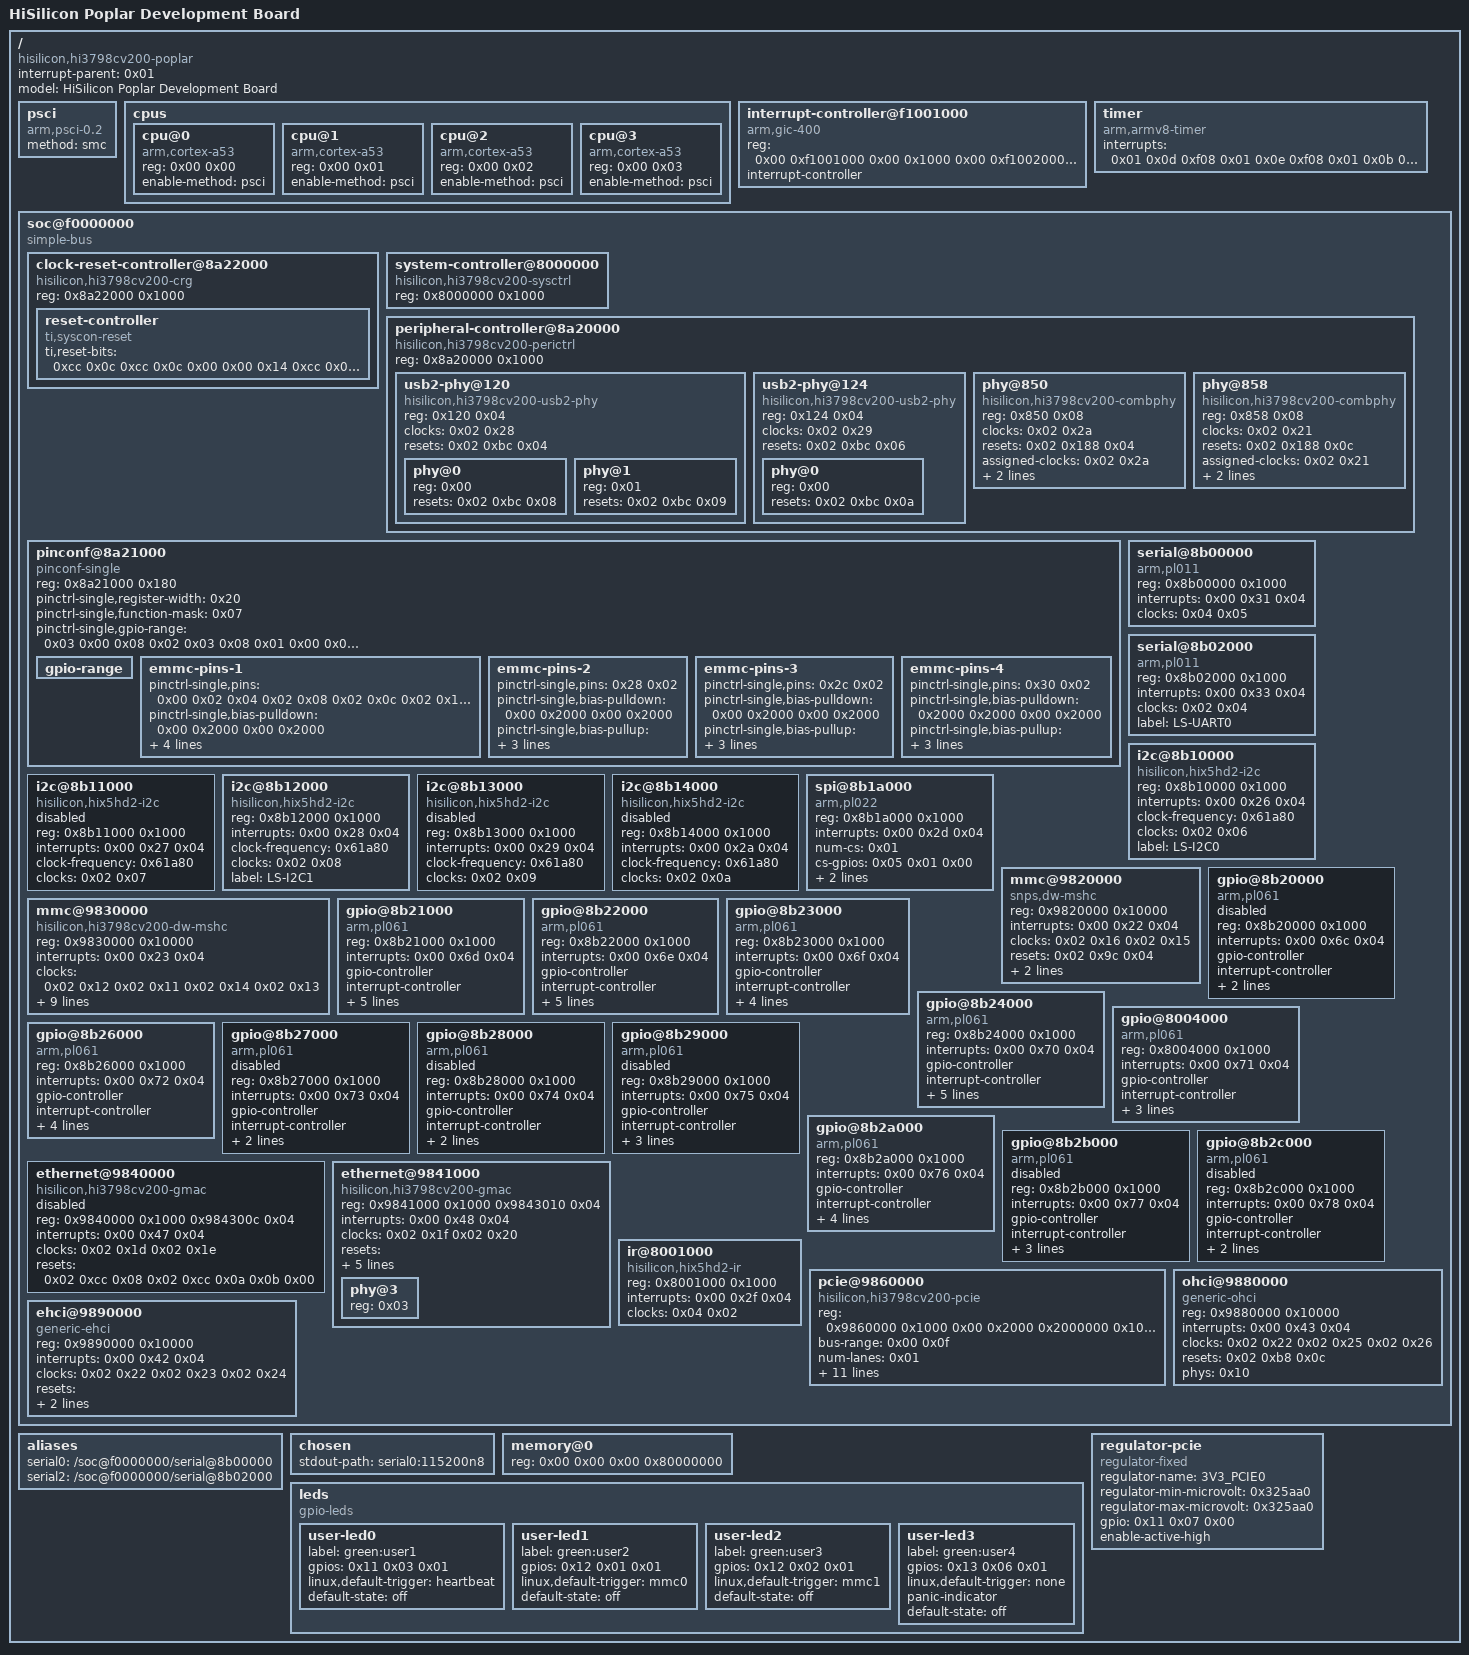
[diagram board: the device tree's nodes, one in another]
/dts-v1/;

/ {
	compatible = "hisilicon,hi3798cv200-poplar\0hisilicon,hi3798cv200";
	interrupt-parent = <0x01>;
	#address-cells = <0x02>;
	#size-cells = <0x02>;
	model = "HiSilicon Poplar Development Board";

	psci {
		compatible = "arm,psci-0.2";
		method = "smc";
	};

	cpus {
		#address-cells = <0x02>;
		#size-cells = <0x00>;

		cpu@0 {
			compatible = "arm,cortex-a53";
			device_type = "cpu";
			reg = <0x00 0x00>;
			enable-method = "psci";
		};

		cpu@1 {
			compatible = "arm,cortex-a53";
			device_type = "cpu";
			reg = <0x00 0x01>;
			enable-method = "psci";
		};

		cpu@2 {
			compatible = "arm,cortex-a53";
			device_type = "cpu";
			reg = <0x00 0x02>;
			enable-method = "psci";
		};

		cpu@3 {
			compatible = "arm,cortex-a53";
			device_type = "cpu";
			reg = <0x00 0x03>;
			enable-method = "psci";
		};
	};

	interrupt-controller@f1001000 {
		compatible = "arm,gic-400";
		reg = <0x00 0xf1001000 0x00 0x1000 0x00 0xf1002000 0x00 0x100>;
		#address-cells = <0x00>;
		#interrupt-cells = <0x03>;
		interrupt-controller;
		phandle = <0x01>;
	};

	timer {
		compatible = "arm,armv8-timer";
		interrupts = <0x01 0x0d 0xf08 0x01 0x0e 0xf08 0x01 0x0b 0xf08 0x01 0x0a 0xf08>;
	};

	soc@f0000000 {
		compatible = "simple-bus";
		#address-cells = <0x01>;
		#size-cells = <0x01>;
		ranges = <0x00 0x00 0xf0000000 0x10000000>;
		phandle = <0x14>;

		clock-reset-controller@8a22000 {
			compatible = "hisilicon,hi3798cv200-crg\0syscon\0simple-mfd";
			reg = <0x8a22000 0x1000>;
			#clock-cells = <0x01>;
			#reset-cells = <0x02>;
			phandle = <0x02>;

			reset-controller {
				compatible = "ti,syscon-reset";
				#reset-cells = <0x01>;
				ti,reset-bits = <0xcc 0x0c 0xcc 0x0c 0x00 0x00 0x14 0xcc 0x0d 0xcc 0x0d 0x00 0x00 0x14>;
				phandle = <0x0b>;
			};
		};

		system-controller@8000000 {
			compatible = "hisilicon,hi3798cv200-sysctrl\0syscon";
			reg = <0x8000000 0x1000>;
			#clock-cells = <0x01>;
			#reset-cells = <0x02>;
			phandle = <0x04>;
		};

		peripheral-controller@8a20000 {
			compatible = "hisilicon,hi3798cv200-perictrl\0syscon\0simple-mfd";
			reg = <0x8a20000 0x1000>;
			#address-cells = <0x01>;
			#size-cells = <0x01>;
			ranges = <0x00 0x8a20000 0x1000>;
			phandle = <0x15>;

			usb2-phy@120 {
				compatible = "hisilicon,hi3798cv200-usb2-phy";
				reg = <0x120 0x04>;
				clocks = <0x02 0x28>;
				resets = <0x02 0xbc 0x04>;
				#address-cells = <0x01>;
				#size-cells = <0x00>;
				phandle = <0x16>;

				phy@0 {
					reg = <0x00>;
					#phy-cells = <0x00>;
					resets = <0x02 0xbc 0x08>;
					phandle = <0x10>;
				};

				phy@1 {
					reg = <0x01>;
					#phy-cells = <0x00>;
					resets = <0x02 0xbc 0x09>;
					phandle = <0x17>;
				};
			};

			usb2-phy@124 {
				compatible = "hisilicon,hi3798cv200-usb2-phy";
				reg = <0x124 0x04>;
				clocks = <0x02 0x29>;
				resets = <0x02 0xbc 0x06>;
				#address-cells = <0x01>;
				#size-cells = <0x00>;
				phandle = <0x18>;

				phy@0 {
					reg = <0x00>;
					#phy-cells = <0x00>;
					resets = <0x02 0xbc 0x0a>;
					phandle = <0x19>;
				};
			};

			phy@850 {
				compatible = "hisilicon,hi3798cv200-combphy";
				reg = <0x850 0x08>;
				#phy-cells = <0x01>;
				clocks = <0x02 0x2a>;
				resets = <0x02 0x188 0x04>;
				assigned-clocks = <0x02 0x2a>;
				assigned-clock-rates = <0x5f5e100>;
				hisilicon,fixed-mode = <0x04>;
				phandle = <0x1a>;
			};

			phy@858 {
				compatible = "hisilicon,hi3798cv200-combphy";
				reg = <0x858 0x08>;
				#phy-cells = <0x01>;
				clocks = <0x02 0x21>;
				resets = <0x02 0x188 0x0c>;
				assigned-clocks = <0x02 0x21>;
				assigned-clock-rates = <0x5f5e100>;
				hisilicon,mode-select-bits = <0x08 0x0b 0x1800>;
				phandle = <0x0d>;
			};
		};

		pinconf@8a21000 {
			compatible = "pinconf-single";
			reg = <0x8a21000 0x180>;
			pinctrl-single,register-width = <0x20>;
			pinctrl-single,function-mask = <0x07>;
			pinctrl-single,gpio-range = <0x03 0x00 0x08 0x02 0x03 0x08 0x01 0x00 0x03 0x09 0x04 0x02 0x03 0x0d 0x01 0x00 0x03 0x0e 0x01 0x01 0x03 0x0f 0x01 0x00 0x03 0x10 0x05 0x00 0x03 0x15 0x03 0x01 0x03 0x18 0x04 0x01 0x03 0x1c 0x02 0x02 0x03 0x56 0x01 0x01 0x03 0x57 0x01 0x00 0x03 0x1e 0x04 0x02 0x03 0x22 0x03 0x00 0x03 0x25 0x01 0x02 0x03 0x26 0x03 0x02 0x03 0x29 0x05 0x00 0x03 0x2e 0x08 0x01 0x03 0x36 0x08 0x01 0x03 0x40 0x07 0x01 0x03 0x47 0x01 0x00 0x03 0x48 0x06 0x01 0x03 0x4e 0x01 0x00 0x03 0x4f 0x01 0x01 0x03 0x50 0x06 0x01 0x03 0x46 0x02 0x01 0x03 0x58 0x08 0x00>;
			phandle = <0x0a>;

			gpio-range {
				#pinctrl-single,gpio-range-cells = <0x03>;
				phandle = <0x03>;
			};

			emmc-pins-1 {
				pinctrl-single,pins = <0x00 0x02 0x04 0x02 0x08 0x02 0x0c 0x02 0x10 0x02 0x14 0x02 0x18 0x02 0x1c 0x02 0x24 0x02>;
				pinctrl-single,bias-pulldown = <0x00 0x2000 0x00 0x2000>;
				pinctrl-single,bias-pullup = <0x00 0x1000 0x00 0x1000>;
				pinctrl-single,slew-rate = <0x100 0x100>;
				pinctrl-single,drive-strength = <0xb0 0xf0>;
				phandle = <0x06>;
			};

			emmc-pins-2 {
				pinctrl-single,pins = <0x28 0x02>;
				pinctrl-single,bias-pulldown = <0x00 0x2000 0x00 0x2000>;
				pinctrl-single,bias-pullup = <0x00 0x1000 0x00 0x1000>;
				pinctrl-single,slew-rate = <0x100 0x100>;
				pinctrl-single,drive-strength = <0x90 0xf0>;
				phandle = <0x07>;
			};

			emmc-pins-3 {
				pinctrl-single,pins = <0x2c 0x02>;
				pinctrl-single,bias-pulldown = <0x00 0x2000 0x00 0x2000>;
				pinctrl-single,bias-pullup = <0x00 0x1000 0x00 0x1000>;
				pinctrl-single,slew-rate = <0x100 0x100>;
				pinctrl-single,drive-strength = <0x30 0x30>;
				phandle = <0x08>;
			};

			emmc-pins-4 {
				pinctrl-single,pins = <0x30 0x02>;
				pinctrl-single,bias-pulldown = <0x2000 0x2000 0x00 0x2000>;
				pinctrl-single,bias-pullup = <0x00 0x1000 0x00 0x1000>;
				pinctrl-single,slew-rate = <0x100 0x100>;
				pinctrl-single,drive-strength = <0x30 0x30>;
				phandle = <0x09>;
			};
		};

		serial@8b00000 {
			compatible = "arm,pl011\0arm,primecell";
			reg = <0x8b00000 0x1000>;
			interrupts = <0x00 0x31 0x04>;
			clocks = <0x04 0x05>;
			clock-names = "apb_pclk";
			status = "okay";
			phandle = <0x1b>;
		};

		serial@8b02000 {
			compatible = "arm,pl011\0arm,primecell";
			reg = <0x8b02000 0x1000>;
			interrupts = <0x00 0x33 0x04>;
			clocks = <0x02 0x04>;
			clock-names = "apb_pclk";
			status = "okay";
			label = "LS-UART0";
			phandle = <0x1c>;
		};

		i2c@8b10000 {
			compatible = "hisilicon,hix5hd2-i2c";
			reg = <0x8b10000 0x1000>;
			#address-cells = <0x01>;
			#size-cells = <0x00>;
			interrupts = <0x00 0x26 0x04>;
			clock-frequency = <0x61a80>;
			clocks = <0x02 0x06>;
			status = "okay";
			label = "LS-I2C0";
			phandle = <0x1d>;
		};

		i2c@8b11000 {
			compatible = "hisilicon,hix5hd2-i2c";
			reg = <0x8b11000 0x1000>;
			#address-cells = <0x01>;
			#size-cells = <0x00>;
			interrupts = <0x00 0x27 0x04>;
			clock-frequency = <0x61a80>;
			clocks = <0x02 0x07>;
			status = "disabled";
			phandle = <0x1e>;
		};

		i2c@8b12000 {
			compatible = "hisilicon,hix5hd2-i2c";
			reg = <0x8b12000 0x1000>;
			#address-cells = <0x01>;
			#size-cells = <0x00>;
			interrupts = <0x00 0x28 0x04>;
			clock-frequency = <0x61a80>;
			clocks = <0x02 0x08>;
			status = "okay";
			label = "LS-I2C1";
			phandle = <0x1f>;
		};

		i2c@8b13000 {
			compatible = "hisilicon,hix5hd2-i2c";
			reg = <0x8b13000 0x1000>;
			#address-cells = <0x01>;
			#size-cells = <0x00>;
			interrupts = <0x00 0x29 0x04>;
			clock-frequency = <0x61a80>;
			clocks = <0x02 0x09>;
			status = "disabled";
			phandle = <0x20>;
		};

		i2c@8b14000 {
			compatible = "hisilicon,hix5hd2-i2c";
			reg = <0x8b14000 0x1000>;
			#address-cells = <0x01>;
			#size-cells = <0x00>;
			interrupts = <0x00 0x2a 0x04>;
			clock-frequency = <0x61a80>;
			clocks = <0x02 0x0a>;
			status = "disabled";
			phandle = <0x21>;
		};

		spi@8b1a000 {
			compatible = "arm,pl022\0arm,primecell";
			reg = <0x8b1a000 0x1000>;
			interrupts = <0x00 0x2d 0x04>;
			num-cs = <0x01>;
			cs-gpios = <0x05 0x01 0x00>;
			clocks = <0x02 0x0c>;
			clock-names = "apb_pclk";
			#address-cells = <0x01>;
			#size-cells = <0x00>;
			status = "okay";
			label = "LS-SPI0";
			phandle = <0x22>;
		};

		mmc@9820000 {
			compatible = "snps,dw-mshc";
			reg = <0x9820000 0x10000>;
			interrupts = <0x00 0x22 0x04>;
			clocks = <0x02 0x16 0x02 0x15>;
			clock-names = "ciu\0biu";
			resets = <0x02 0x9c 0x04>;
			reset-names = "reset";
			status = "okay";
			bus-width = <0x04>;
			cap-sd-highspeed;
			phandle = <0x23>;
		};

		mmc@9830000 {
			compatible = "hisilicon,hi3798cv200-dw-mshc";
			reg = <0x9830000 0x10000>;
			interrupts = <0x00 0x23 0x04>;
			clocks = <0x02 0x12 0x02 0x11 0x02 0x14 0x02 0x13>;
			clock-names = "ciu\0biu\0ciu-sample\0ciu-drive";
			resets = <0x02 0xa0 0x04>;
			reset-names = "reset";
			status = "okay";
			pinctrl-names = "default";
			pinctrl-0 = <0x06 0x07 0x08 0x09>;
			fifo-depth = <0x100>;
			clock-frequency = <0xbebc200>;
			cap-mmc-highspeed;
			mmc-ddr-1_8v;
			mmc-hs200-1_8v;
			non-removable;
			bus-width = <0x08>;
			phandle = <0x24>;
		};

		gpio@8b20000 {
			compatible = "arm,pl061\0arm,primecell";
			reg = <0x8b20000 0x1000>;
			interrupts = <0x00 0x6c 0x04>;
			gpio-controller;
			#gpio-cells = <0x02>;
			interrupt-controller;
			#interrupt-cells = <0x02>;
			gpio-ranges = <0x0a 0x00 0x00 0x08>;
			clocks = <0x02 0x01>;
			clock-names = "apb_pclk";
			status = "disabled";
			phandle = <0x25>;
		};

		gpio@8b21000 {
			compatible = "arm,pl061\0arm,primecell";
			reg = <0x8b21000 0x1000>;
			interrupts = <0x00 0x6d 0x04>;
			gpio-controller;
			#gpio-cells = <0x02>;
			interrupt-controller;
			#interrupt-cells = <0x02>;
			gpio-ranges = <0x0a 0x00 0x08 0x01 0x0a 0x01 0x09 0x04 0x0a 0x05 0x0d 0x01 0x0a 0x06 0x0e 0x01 0x0a 0x07 0x0f 0x01>;
			clocks = <0x02 0x01>;
			clock-names = "apb_pclk";
			status = "okay";
			gpio-line-names = "GPIO-E\0\0\0\0\0GPIO-F\0\0GPIO-J";
			phandle = <0x26>;
		};

		gpio@8b22000 {
			compatible = "arm,pl061\0arm,primecell";
			reg = <0x8b22000 0x1000>;
			interrupts = <0x00 0x6e 0x04>;
			gpio-controller;
			#gpio-cells = <0x02>;
			interrupt-controller;
			#interrupt-cells = <0x02>;
			gpio-ranges = <0x0a 0x00 0x10 0x05 0x0a 0x05 0x15 0x03>;
			clocks = <0x02 0x01>;
			clock-names = "apb_pclk";
			status = "okay";
			gpio-line-names = "GPIO-H\0GPIO-I\0GPIO-L\0GPIO-G\0GPIO-K\0\0\0";
			phandle = <0x27>;
		};

		gpio@8b23000 {
			compatible = "arm,pl061\0arm,primecell";
			reg = <0x8b23000 0x1000>;
			interrupts = <0x00 0x6f 0x04>;
			gpio-controller;
			#gpio-cells = <0x02>;
			interrupt-controller;
			#interrupt-cells = <0x02>;
			gpio-ranges = <0x0a 0x00 0x18 0x04 0x0a 0x04 0x1c 0x02 0x0a 0x06 0x56 0x01 0x0a 0x07 0x57 0x01>;
			clocks = <0x02 0x01>;
			clock-names = "apb_pclk";
			status = "okay";
			gpio-line-names = "\0\0\0\0GPIO-C\0\0\0GPIO-B";
			phandle = <0x28>;
		};

		gpio@8b24000 {
			compatible = "arm,pl061\0arm,primecell";
			reg = <0x8b24000 0x1000>;
			interrupts = <0x00 0x70 0x04>;
			gpio-controller;
			#gpio-cells = <0x02>;
			interrupt-controller;
			#interrupt-cells = <0x02>;
			gpio-ranges = <0x0a 0x00 0x1e 0x04 0x0a 0x04 0x22 0x03 0x0a 0x07 0x25 0x01>;
			clocks = <0x02 0x01>;
			clock-names = "apb_pclk";
			status = "okay";
			gpio-line-names = [00 00 00 00 00 47 50 49 4f 2d 44 00 00 00];
			phandle = <0x0e>;
		};

		gpio@8004000 {
			compatible = "arm,pl061\0arm,primecell";
			reg = <0x8004000 0x1000>;
			interrupts = <0x00 0x71 0x04>;
			gpio-controller;
			#gpio-cells = <0x02>;
			interrupt-controller;
			#interrupt-cells = <0x02>;
			clocks = <0x02 0x01>;
			clock-names = "apb_pclk";
			status = "okay";
			gpio-line-names = "\0USER-LED-1\0USER-LED-2\0\0\0GPIO-A\0\0";
			phandle = <0x12>;
		};

		gpio@8b26000 {
			compatible = "arm,pl061\0arm,primecell";
			reg = <0x8b26000 0x1000>;
			interrupts = <0x00 0x72 0x04>;
			gpio-controller;
			#gpio-cells = <0x02>;
			interrupt-controller;
			#interrupt-cells = <0x02>;
			gpio-ranges = <0x0a 0x00 0x26 0x03 0x0a 0x00 0x29 0x05>;
			clocks = <0x02 0x01>;
			clock-names = "apb_pclk";
			status = "okay";
			gpio-line-names = "\0\0\0USER-LED-0\0\0\0\0";
			phandle = <0x11>;
		};

		gpio@8b27000 {
			compatible = "arm,pl061\0arm,primecell";
			reg = <0x8b27000 0x1000>;
			interrupts = <0x00 0x73 0x04>;
			gpio-controller;
			#gpio-cells = <0x02>;
			interrupt-controller;
			#interrupt-cells = <0x02>;
			gpio-ranges = <0x0a 0x00 0x2e 0x08>;
			clocks = <0x02 0x01>;
			clock-names = "apb_pclk";
			status = "disabled";
			phandle = <0x05>;
		};

		gpio@8b28000 {
			compatible = "arm,pl061\0arm,primecell";
			reg = <0x8b28000 0x1000>;
			interrupts = <0x00 0x74 0x04>;
			gpio-controller;
			#gpio-cells = <0x02>;
			interrupt-controller;
			#interrupt-cells = <0x02>;
			gpio-ranges = <0x0a 0x00 0x36 0x08>;
			clocks = <0x02 0x01>;
			clock-names = "apb_pclk";
			status = "disabled";
			phandle = <0x29>;
		};

		gpio@8b29000 {
			compatible = "arm,pl061\0arm,primecell";
			reg = <0x8b29000 0x1000>;
			interrupts = <0x00 0x75 0x04>;
			gpio-controller;
			#gpio-cells = <0x02>;
			interrupt-controller;
			#interrupt-cells = <0x02>;
			gpio-ranges = <0x0a 0x00 0x40 0x07 0x0a 0x47 0x01>;
			clocks = <0x02 0x01>;
			clock-names = "apb_pclk";
			status = "disabled";
			phandle = <0x2a>;
		};

		gpio@8b2a000 {
			compatible = "arm,pl061\0arm,primecell";
			reg = <0x8b2a000 0x1000>;
			interrupts = <0x00 0x76 0x04>;
			gpio-controller;
			#gpio-cells = <0x02>;
			interrupt-controller;
			#interrupt-cells = <0x02>;
			gpio-ranges = <0x0a 0x00 0x48 0x06 0x0a 0x06 0x4e 0x01 0x0a 0x07 0x4f 0x01>;
			clocks = <0x02 0x01>;
			clock-names = "apb_pclk";
			status = "okay";
			gpio-line-names = "\0\0\0\0\0\0USER-LED-3\0";
			phandle = <0x13>;
		};

		gpio@8b2b000 {
			compatible = "arm,pl061\0arm,primecell";
			reg = <0x8b2b000 0x1000>;
			interrupts = <0x00 0x77 0x04>;
			gpio-controller;
			#gpio-cells = <0x02>;
			interrupt-controller;
			#interrupt-cells = <0x02>;
			gpio-ranges = <0x0a 0x00 0x50 0x06 0x0a 0x06 0x46 0x02>;
			clocks = <0x02 0x01>;
			clock-names = "apb_pclk";
			status = "disabled";
			phandle = <0x2b>;
		};

		gpio@8b2c000 {
			compatible = "arm,pl061\0arm,primecell";
			reg = <0x8b2c000 0x1000>;
			interrupts = <0x00 0x78 0x04>;
			gpio-controller;
			#gpio-cells = <0x02>;
			interrupt-controller;
			#interrupt-cells = <0x02>;
			gpio-ranges = <0x0a 0x00 0x58 0x08>;
			clocks = <0x02 0x01>;
			clock-names = "apb_pclk";
			status = "disabled";
			phandle = <0x2c>;
		};

		ethernet@9840000 {
			compatible = "hisilicon,hi3798cv200-gmac\0hisilicon,hisi-gmac-v2";
			reg = <0x9840000 0x1000 0x984300c 0x04>;
			interrupts = <0x00 0x47 0x04>;
			clocks = <0x02 0x1d 0x02 0x1e>;
			clock-names = "mac_core\0mac_ifc";
			resets = <0x02 0xcc 0x08 0x02 0xcc 0x0a 0x0b 0x00>;
			reset-names = "mac_core\0mac_ifc\0phy";
			status = "disabled";
			phandle = <0x2d>;
		};

		ethernet@9841000 {
			compatible = "hisilicon,hi3798cv200-gmac\0hisilicon,hisi-gmac-v2";
			reg = <0x9841000 0x1000 0x9843010 0x04>;
			interrupts = <0x00 0x48 0x04>;
			clocks = <0x02 0x1f 0x02 0x20>;
			clock-names = "mac_core\0mac_ifc";
			resets = <0x02 0xcc 0x09 0x02 0xcc 0x0b 0x0b 0x01>;
			reset-names = "mac_core\0mac_ifc\0phy";
			status = "okay";
			#address-cells = <0x01>;
			#size-cells = <0x00>;
			phy-handle = <0x0c>;
			phy-mode = "rgmii";
			hisilicon,phy-reset-delays-us = <0x2710 0x2710 0x7530>;
			phandle = <0x2e>;

			phy@3 {
				reg = <0x03>;
				phandle = <0x0c>;
			};
		};

		ir@8001000 {
			compatible = "hisilicon,hix5hd2-ir";
			reg = <0x8001000 0x1000>;
			interrupts = <0x00 0x2f 0x04>;
			clocks = <0x04 0x02>;
			status = "okay";
			phandle = <0x2f>;
		};

		pcie@9860000 {
			compatible = "hisilicon,hi3798cv200-pcie";
			reg = <0x9860000 0x1000 0x00 0x2000 0x2000000 0x1000000>;
			reg-names = "control\0rc-dbi\0config";
			#address-cells = <0x03>;
			#size-cells = <0x02>;
			device_type = "pci";
			bus-range = <0x00 0x0f>;
			num-lanes = <0x01>;
			ranges = <0x81000000 0x00 0x00 0x4f00000 0x00 0x100000 0x82000000 0x00 0x3000000 0x3000000 0x00 0x1f00000>;
			interrupts = <0x00 0x80 0x04>;
			interrupt-names = "msi";
			#interrupt-cells = <0x01>;
			interrupt-map-mask = <0x00 0x00 0x00 0x00>;
			interrupt-map = <0x00 0x00 0x00 0x00 0x01 0x00 0x83 0x04>;
			clocks = <0x02 0x19 0x02 0x1a 0x02 0x1b 0x02 0x1c>;
			clock-names = "aux\0pipe\0sys\0bus";
			resets = <0x02 0x18c 0x06 0x02 0x18c 0x05 0x02 0x18c 0x04>;
			reset-names = "soft\0sys\0bus";
			phys = <0x0d 0x02>;
			phy-names = "phy";
			status = "okay";
			reset-gpios = <0x0e 0x04 0x00>;
			vpcie-supply = <0x0f>;
			phandle = <0x30>;
		};

		ohci@9880000 {
			compatible = "generic-ohci";
			reg = <0x9880000 0x10000>;
			interrupts = <0x00 0x43 0x04>;
			clocks = <0x02 0x22 0x02 0x25 0x02 0x26>;
			clock-names = "bus\0clk12\0clk48";
			resets = <0x02 0xb8 0x0c>;
			reset-names = "bus";
			phys = <0x10>;
			phy-names = "usb";
			status = "okay";
			phandle = <0x31>;
		};

		ehci@9890000 {
			compatible = "generic-ehci";
			reg = <0x9890000 0x10000>;
			interrupts = <0x00 0x42 0x04>;
			clocks = <0x02 0x22 0x02 0x23 0x02 0x24>;
			clock-names = "bus\0phy\0utmi";
			resets = <0x02 0xb8 0x0c 0x02 0xb8 0x10 0x02 0xb8 0x0d>;
			reset-names = "bus\0phy\0utmi";
			phys = <0x10>;
			phy-names = "usb";
			status = "okay";
			phandle = <0x32>;
		};
	};

	aliases {
		serial0 = "/soc@f0000000/serial@8b00000";
		serial2 = "/soc@f0000000/serial@8b02000";
	};

	chosen {
		stdout-path = "serial0:115200n8";
	};

	memory@0 {
		device_type = "memory";
		reg = <0x00 0x00 0x00 0x80000000>;
	};

	leds {
		compatible = "gpio-leds";

		user-led0 {
			label = "green:user1";
			gpios = <0x11 0x03 0x01>;
			linux,default-trigger = "heartbeat";
			default-state = "off";
		};

		user-led1 {
			label = "green:user2";
			gpios = <0x12 0x01 0x01>;
			linux,default-trigger = "mmc0";
			default-state = "off";
		};

		user-led2 {
			label = "green:user3";
			gpios = <0x12 0x02 0x01>;
			linux,default-trigger = "mmc1";
			default-state = "off";
		};

		user-led3 {
			label = "green:user4";
			gpios = <0x13 0x06 0x01>;
			linux,default-trigger = "none";
			panic-indicator;
			default-state = "off";
		};
	};

	regulator-pcie {
		compatible = "regulator-fixed";
		regulator-name = "3V3_PCIE0";
		regulator-min-microvolt = <0x325aa0>;
		regulator-max-microvolt = <0x325aa0>;
		gpio = <0x11 0x07 0x00>;
		enable-active-high;
		phandle = <0x0f>;
	};

	__symbols__ {
		gic = "/interrupt-controller@f1001000";
		soc = "/soc@f0000000";
		crg = "/soc@f0000000/clock-reset-controller@8a22000";
		gmacphyrst = "/soc@f0000000/clock-reset-controller@8a22000/reset-controller";
		sysctrl = "/soc@f0000000/system-controller@8000000";
		perictrl = "/soc@f0000000/peripheral-controller@8a20000";
		usb2_phy1 = "/soc@f0000000/peripheral-controller@8a20000/usb2-phy@120";
		usb2_phy1_port0 = "/soc@f0000000/peripheral-controller@8a20000/usb2-phy@120/phy@0";
		usb2_phy1_port1 = "/soc@f0000000/peripheral-controller@8a20000/usb2-phy@120/phy@1";
		usb2_phy2 = "/soc@f0000000/peripheral-controller@8a20000/usb2-phy@124";
		usb2_phy2_port0 = "/soc@f0000000/peripheral-controller@8a20000/usb2-phy@124/phy@0";
		combphy0 = "/soc@f0000000/peripheral-controller@8a20000/phy@850";
		combphy1 = "/soc@f0000000/peripheral-controller@8a20000/phy@858";
		pmx0 = "/soc@f0000000/pinconf@8a21000";
		range = "/soc@f0000000/pinconf@8a21000/gpio-range";
		emmc_pins_1 = "/soc@f0000000/pinconf@8a21000/emmc-pins-1";
		emmc_pins_2 = "/soc@f0000000/pinconf@8a21000/emmc-pins-2";
		emmc_pins_3 = "/soc@f0000000/pinconf@8a21000/emmc-pins-3";
		emmc_pins_4 = "/soc@f0000000/pinconf@8a21000/emmc-pins-4";
		uart0 = "/soc@f0000000/serial@8b00000";
		uart2 = "/soc@f0000000/serial@8b02000";
		i2c0 = "/soc@f0000000/i2c@8b10000";
		i2c1 = "/soc@f0000000/i2c@8b11000";
		i2c2 = "/soc@f0000000/i2c@8b12000";
		i2c3 = "/soc@f0000000/i2c@8b13000";
		i2c4 = "/soc@f0000000/i2c@8b14000";
		spi0 = "/soc@f0000000/spi@8b1a000";
		sd0 = "/soc@f0000000/mmc@9820000";
		emmc = "/soc@f0000000/mmc@9830000";
		gpio0 = "/soc@f0000000/gpio@8b20000";
		gpio1 = "/soc@f0000000/gpio@8b21000";
		gpio2 = "/soc@f0000000/gpio@8b22000";
		gpio3 = "/soc@f0000000/gpio@8b23000";
		gpio4 = "/soc@f0000000/gpio@8b24000";
		gpio5 = "/soc@f0000000/gpio@8004000";
		gpio6 = "/soc@f0000000/gpio@8b26000";
		gpio7 = "/soc@f0000000/gpio@8b27000";
		gpio8 = "/soc@f0000000/gpio@8b28000";
		gpio9 = "/soc@f0000000/gpio@8b29000";
		gpio10 = "/soc@f0000000/gpio@8b2a000";
		gpio11 = "/soc@f0000000/gpio@8b2b000";
		gpio12 = "/soc@f0000000/gpio@8b2c000";
		gmac0 = "/soc@f0000000/ethernet@9840000";
		gmac1 = "/soc@f0000000/ethernet@9841000";
		eth_phy1 = "/soc@f0000000/ethernet@9841000/phy@3";
		ir = "/soc@f0000000/ir@8001000";
		pcie = "/soc@f0000000/pcie@9860000";
		ohci = "/soc@f0000000/ohci@9880000";
		ehci = "/soc@f0000000/ehci@9890000";
		reg_pcie = "/regulator-pcie";
	};
};
